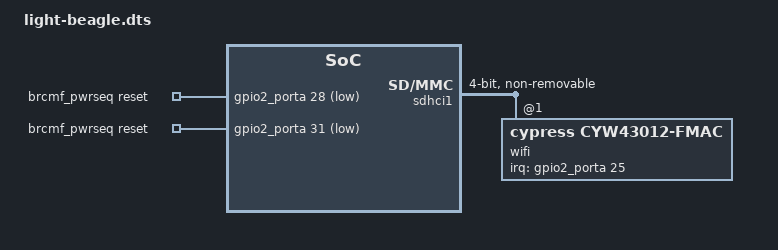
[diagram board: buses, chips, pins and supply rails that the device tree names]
/* SPDX-License-Identifier: GPL-2.0 */
/*
 * Copyright (C) 2021 Alibaba Group Holding Limited.
 */

/dts-v1/;

#include <dt-bindings/gpio/gpio.h>
#include <dt-bindings/interrupt-controller/irq.h>
#include "light-ant-evt.dts"

/ {
	brcmf_pwrseq: brcmf_pwrseq {
		compatible = "mmc-pwrseq-simple";
		reset-gpios = <&gpio2_porta 28 GPIO_ACTIVE_LOW>,	/* BT-REG-ON */
			      <&gpio2_porta 31 GPIO_ACTIVE_LOW>;	/* WL-REG-ON */
	};
};

&sdhci1 {
	#address-cells = <1>;
	#size-cells = <0>;
	status = "okay";

	non-removable;
	bus-width = <4>;
	max-frequency = <100000000>;
	cap-sd-highspeed;
	no-sd;
	no-mmc;
	keep-power-in-suspend;
	wakeup-source;
	mmc-pwrseq = <&brcmf_pwrseq>;

	/* New... */
	pull_up;
	io_fixed_1v8;
	wprtn_ignore;

	wifi@1 {
		status = "okay";
		reg = <1>;
		compatible = "cypress,cyw43012-fmac", "brcm,bcm4329-fmac";

		interrupt-parent = <&gpio2_porta>;
		interrupts = <25 IRQ_TYPE_EDGE_FALLING>;
		interrupt-names = "host-wake";
	};
};

